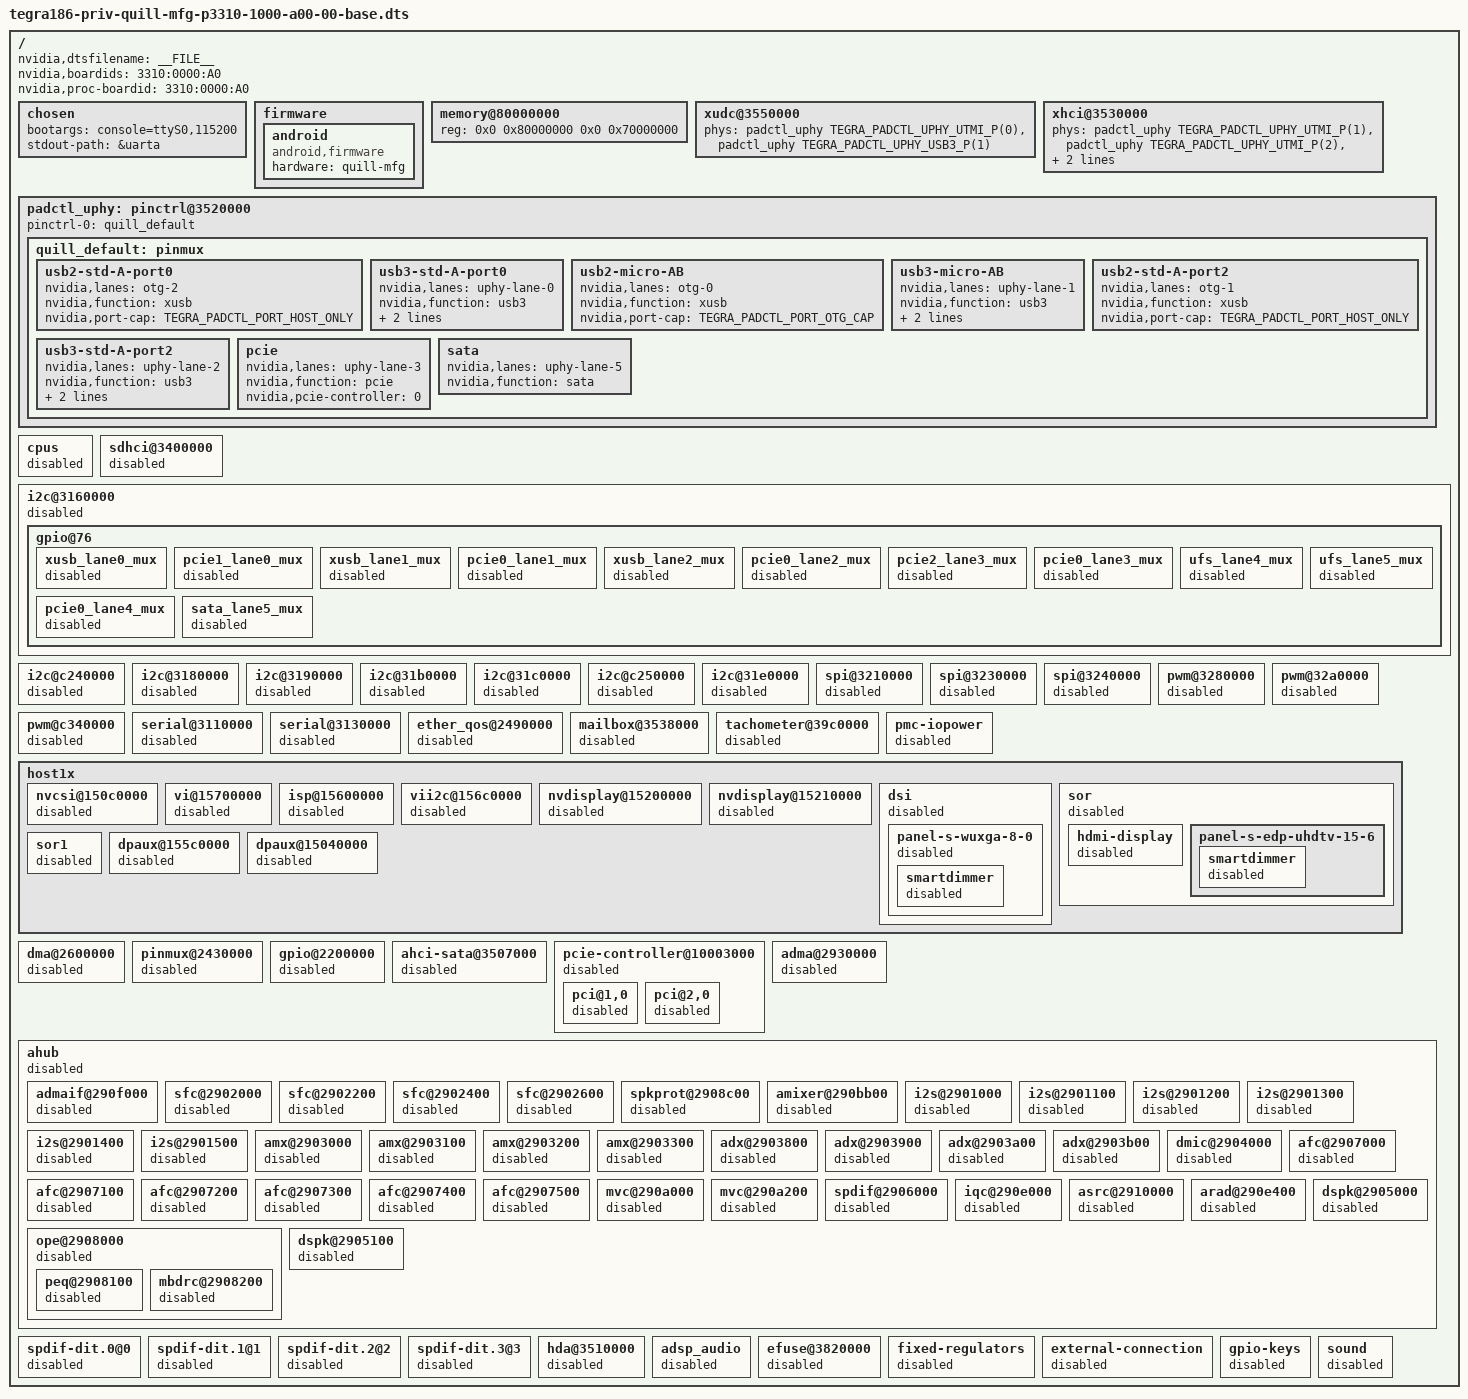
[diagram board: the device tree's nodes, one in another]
/*
 * tegra186-quill-p3310-a00-00-base.dts Quill-MFG A00 Board
 *
 * Copyright (c) 2015-2016, NVIDIA CORPORATION.  All rights reserved.
 *
 * This program is free software; you can redistribute it and/or modify
 * it under the terms of the GNU General Public License as published by
 * the Free Software Foundation; version 2 of the License.
 *
 * This program is distributed in the hope that it will be useful, but WITHOUT
 * ANY WARRANTY; without even the implied warranty of MERCHANTABILITY or
 * FITNESS FOR A PARTICULAR PURPOSE.  See the GNU General Public License for
 * more details.
 */

#include "tegra186-platforms/tegra186-quill-common-p3310-1000-a00.dtsi"
#include "tegra186-platforms/tegra186-quill-mfg-power-tree-p3310-1000-a00-00.dtsi"
#include "tegra186-plugin-manager/tegra186-quill-p3310-1000-a00-plugin-manager.dtsi"

/ {
	nvidia,dtsfilename = __FILE__;
	nvidia,boardids = "3310:0000:A0";
	nvidia,proc-boardid = "3310:0000:A0";

	chosen {
		bootargs ="console=ttyS0,115200";
		stdout-path = &uarta;
	};

	firmware {
		android {
			compatible = "android,firmware";
			hardware = "quill-mfg";
		};
	};

	memory@80000000 {
		device_type = "memory";
		reg = <0x0 0x80000000 0x0 0x70000000>;
	};

	xudc@3550000 {
		status = "okay";
		phys = <&padctl_uphy TEGRA_PADCTL_UPHY_UTMI_P(0)>,
			<&padctl_uphy TEGRA_PADCTL_UPHY_USB3_P(1)>;
		phy-names = "usb2", "usb3";
	};

	xhci@3530000 {
		status = "okay";
		phys = <&padctl_uphy TEGRA_PADCTL_UPHY_UTMI_P(1)>,
			<&padctl_uphy TEGRA_PADCTL_UPHY_UTMI_P(2)>,
			<&padctl_uphy TEGRA_PADCTL_UPHY_USB3_P(0)>,
			<&padctl_uphy TEGRA_PADCTL_UPHY_USB3_P(2)>;
		phy-names = "utmi-1", "utmi-2", "usb3-0", "usb3-2";
	};

	padctl_uphy: pinctrl@3520000 {
		status = "okay";
		pinctrl-0 = <&quill_default>;
		pinctrl-names = "default";
		quill_default: pinmux {
			usb2-std-A-port0 {
				nvidia,lanes = "otg-2";
				nvidia,function = "xusb";
				nvidia,port-cap = <TEGRA_PADCTL_PORT_HOST_ONLY>;
			};
			usb3-std-A-port0 {
				nvidia,lanes = "uphy-lane-0";
				nvidia,function = "usb3";
				nvidia,usb3-port = <0>;
				nvidia,port-cap = <TEGRA_PADCTL_PORT_HOST_ONLY>;
			};
			usb2-micro-AB {
				nvidia,lanes = "otg-0";
				nvidia,function = "xusb";
				nvidia,port-cap = <TEGRA_PADCTL_PORT_OTG_CAP>;
			};
			usb3-micro-AB {
				nvidia,lanes = "uphy-lane-1";
				nvidia,function = "usb3";
				nvidia,usb3-port = <1>;
				nvidia,port-cap = <TEGRA_PADCTL_PORT_OTG_CAP>;
			};
			usb2-std-A-port2 {
				nvidia,lanes = "otg-1";
				nvidia,function = "xusb";
				nvidia,port-cap = <TEGRA_PADCTL_PORT_HOST_ONLY>;
			};
			usb3-std-A-port2 {
				nvidia,lanes = "uphy-lane-2";
				nvidia,function = "usb3";
				nvidia,usb3-port = <2>;
				nvidia,port-cap = <TEGRA_PADCTL_PORT_HOST_ONLY>;
			};
			pcie {
				nvidia,lanes = "uphy-lane-3";
				nvidia,function = "pcie";
				nvidia,pcie-controller = <0>;
			};
			sata {
				nvidia,lanes = "uphy-lane-5";
				nvidia,function = "sata";
			};
		};
	};
	cpus {
		status = "disabled";
	};

	sdhci@3400000 {
		status = "disabled";
	};

	i2c@3160000 {
		status = "disabled";
		gpio@76 {
			xusb_lane0_mux {
				status = "disabled";
			};

			pcie1_lane0_mux {
				status = "disabled";
			};

			xusb_lane1_mux {
				status = "disabled";
			};

			pcie0_lane1_mux {
				status = "disabled";
			};

			xusb_lane2_mux {
				status = "disabled";
			};

			pcie0_lane2_mux {
				status = "disabled";
			};

			pcie2_lane3_mux {
				status = "disabled";
			};

			pcie0_lane3_mux {
				status = "disabled";
			};

			ufs_lane4_mux {
				status = "disabled";
			};

			pcie0_lane4_mux {
				status = "disabled";
			};

			ufs_lane5_mux {
				status = "disabled";
			};

			sata_lane5_mux {
				status = "disabled";
			};
		};
	};

	i2c@c240000 {
		status = "disabled";
	};

	i2c@3180000 {
		status = "disabled";
	};

	i2c@3190000 {
		status = "disabled";
	};

	i2c@31b0000 {
		status = "disabled";
	};

	i2c@31c0000 {
		status = "disabled";
	};

	i2c@c250000 {
		status = "disabled";
	};

	i2c@31e0000 {
		status = "disabled";
	};

	spi@3210000 {
		status = "disabled";
	};

	spi@3230000 {
		status = "disabled";
	};

	spi@3240000 {
		status = "disabled";
	};

	pwm@3280000 {
		status = "disabled";
	};

	pwm@32a0000 {
		status = "disabled";
	};

	pwm@c340000 {
		status = "disabled";
	};


	serial@3110000 {
		status = "disabled";
	};

	serial@3130000 {
		status = "disabled";
	};

	ether_qos@2490000 {
		status = "disabled";
	};

	mailbox@3538000 {
		status = "disabled";
	};

	tachometer@39c0000 {
		status = "disabled";
	};

	pmc-iopower {
		status = "disabled";
	};

	host1x {
		nvcsi@150c0000 {
			status = "disabled";
		};

		vi@15700000 {
			status = "disabled";
		};

		isp@15600000 {
			status = "disabled";
		};

		vii2c@156c0000 {
			status = "disabled";
		};

		nvdisplay@15200000 {
			status = "disabled";
		};

		nvdisplay@15210000 {
			status = "disabled";
		};

		dsi {
			status = "disabled";
			panel-s-wuxga-8-0 {
				status = "disabled";
				smartdimmer {
					status = "disabled";
				};
			};
		};

		sor {
			status = "disabled";
			hdmi-display {
				status = "disabled";
			};

			panel-s-edp-uhdtv-15-6 {
				smartdimmer {
					status = "disabled";
				};
			};
		};

		sor1 {
			status = "disabled";
		};

		dpaux@155c0000 {
			status = "disabled";
		};

		dpaux@15040000 {
			status = "disabled";
		};
	};

	dma@2600000 {
		status = "disabled";
	};

	pinmux@2430000 {
		status = "disabled";
	};

	gpio@2200000 {
		status = "disabled";
	};

	ahci-sata@3507000 {
		status = "disabled";
	};

	pcie-controller@10003000 {
		status = "disabled";

		pci@1,0 {
			status = "disabled";
		};

		pci@2,0 {
			status = "disabled";
		};
	};

	adma@2930000 {
		status = "disabled";
	};

	ahub {
		status = "disabled";

		admaif@290f000 {
			status = "disabled";
		};

		sfc@2902000 {
			status = "disabled";
		};

		sfc@2902200 {
			status = "disabled";
		};

		sfc@2902400 {
			status = "disabled";
		};

		sfc@2902600 {
			status = "disabled";
		};

		spkprot@2908c00 {
			status = "disabled";
		};

		amixer@290bb00 {
			status = "disabled";
		};

		i2s@2901000 {
			status = "disabled";
		};

		i2s@2901100 {
			status = "disabled";
		};

		i2s@2901200 {
			status = "disabled";
		};

		i2s@2901300 {
			status = "disabled";
		};

		i2s@2901400 {
			status = "disabled";
		};

		i2s@2901500 {
			status = "disabled";
		};

		amx@2903000 {
			status = "disabled";
		};

		amx@2903100 {
			status = "disabled";
		};

		amx@2903200 {
			status = "disabled";
		};

		amx@2903300 {
			status = "disabled";
		};

		adx@2903800 {
			status = "disabled";
		};

		adx@2903900 {
			status = "disabled";
		};

		adx@2903a00 {
			status = "disabled";
		};

		adx@2903b00 {
			status = "disabled";
		};

		dmic@2904000 {
			status = "disabled";
		};

		afc@2907000 {
			status = "disabled";
		};

		afc@2907100 {
			status = "disabled";
		};

		afc@2907200 {
			status = "disabled";
		};

		afc@2907300 {
			status = "disabled";
		};

		afc@2907400 {
			status = "disabled";
		};

		afc@2907500 {
			status = "disabled";
		};

		mvc@290a000 {
			status = "disabled";
		};

		mvc@290a200 {
			status = "disabled";
		};

		spdif@2906000 {
			status = "disabled";
		};

		iqc@290e000 {
			status = "disabled";
		};

		asrc@2910000 {
			status = "disabled";
		};

		arad@290e400 {
			status = "disabled";
		};

		ope@2908000 {
			status = "disabled";

			peq@2908100 {
				status = "disabled";
			};

			mbdrc@2908200 {
				status = "disabled";
			};
		};

		dspk@2905000 {
			status = "disabled";
		};

		dspk@2905100 {
			status = "disabled";
		};
	};

	spdif-dit.0@0 {
		status = "disabled";
	};

	spdif-dit.1@1 {
		status = "disabled";
	};

	spdif-dit.2@2 {
		status = "disabled";
	};

	spdif-dit.3@3 {
		status = "disabled";
	};

	hda@3510000 {
		status = "disabled";
	};

	adsp_audio {
		status = "disabled";
	};

        efuse@3820000 {
                status = "disabled";
        };

	fixed-regulators {
		status = "disabled";
	};

	external-connection {
		status = "disabled";
	};

	gpio-keys {
		status = "disabled";
	};

	sound {
		status = "disabled";
	};
};
